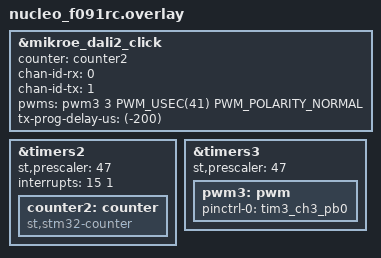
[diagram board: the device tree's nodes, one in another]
/*
 * Copyright 2026 by Sven Hädrich <sven.haedrich@sevenlab.de>
 * SPDX-License-Identifier: Apache-2.0
 *
 * DALI TX is on mikroBUS RST and is driven by a PWM output. pinctrl needs
 * the SoC pin, so this overlay assumes the click is in slot 1 of the
 * arduino_uno_click shield (RST -> A3 -> PB_0).
 */

&mikroe_dali2_click {
	counter = <&counter2>;
	chan-id-rx = <0>;
	chan-id-tx = <1>;
	pwms = <&pwm3 3 PWM_USEC(41) PWM_POLARITY_NORMAL>;
	tx-prog-delay-us = <(-200)>;
};

&timers2 {
	// set timebase to 1us/1MHz
	st,prescaler = <47>;
	status = "okay";
	interrupts = <15 1>;

	counter2: counter {
		compatible = "st,stm32-counter";
		status = "okay";
	};
};

&timers3 {
	// set timebase to 1us/1MHz
	st,prescaler = <47>;
	status = "okay";

	pwm3: pwm {
		pinctrl-0 = <&tim3_ch3_pb0>; // microbus header 1
		pinctrl-names = "default";
		status = "okay";
	};
};
